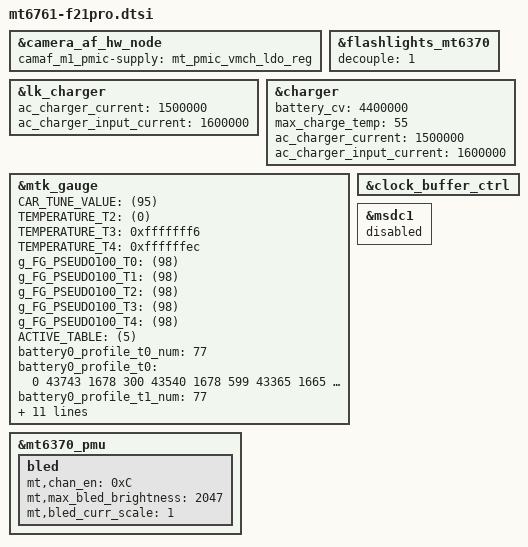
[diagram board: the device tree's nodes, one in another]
// SPDX-License-Identifier: GPL-2.0+
/*
 * Mon Mar 25 18:47:30 CST 2024 stock v4.19.127 boot.img overrides to make identical mt6761.dtb
 *
 * Copyright (c) 2019 MediaTek Inc.
 * Copyright (c) 2025 Jami Kettunen <jami.kettunen@protonmail.com>
 */


// mt6761.dts
&camera_af_hw_node {
	camaf_m1_pmic-supply = <&mt_pmic_vmch_ldo_reg>;
};

&flashlights_mt6370 {
	decouple = <1>;
	/delete-node/ channel@2;
};

&lk_charger {
	/* charging current */
	ac_charger_current = <1500000>;
	ac_charger_input_current = <1600000>;
};
&charger {
	/* common */
	battery_cv = <4400000>;

	/* battery temperature protection */
	max_charge_temp = <55>;

	/* charging current */
	ac_charger_current = <1500000>;
	ac_charger_input_current = <1600000>;
};


// bat_setting/mt6761_battery_prop.dtsi
&mtk_gauge {
	CAR_TUNE_VALUE = <(95)>;
	/* Tune value for current measurement */

	TEMPERATURE_T2 = <(0)>;
	/* Battery temperature T2 */
	TEMPERATURE_T3 = <0xfffffff6>;
	/* Battery temperature T3 */
	TEMPERATURE_T4 = <0xffffffec>;
	/* Battery temperature T4 */
	/delete-property/ TEMPERATURE_T5;
	/* Battery temperature T5 */
	g_FG_PSEUDO100_T0 = <(98)>;
	/* Pseudo 100% percentage at T0 */
	g_FG_PSEUDO100_T1 = <(98)>;
	/* Pseudo 100% percentage at T1 */
	g_FG_PSEUDO100_T2 = <(98)>;
	/* Pseudo 100% percentage at T2 */
	g_FG_PSEUDO100_T3 = <(98)>;
	/* Pseudo 100% percentage at T3 */
	g_FG_PSEUDO100_T4 = <(98)>;
	/* Pseudo 100% percentage at T4 */

	ACTIVE_TABLE = <(5)>;
	/* Table numbers per battery */


	// bat_setting/mt6761_battery_table_ext.dtsi
	battery0_profile_t0_num = <77>;
	battery0_profile_t0 =
	<
	0	43743	1678
	300	43540	1678
	599	43365	1665
	898	43201	1663
	1198	43040	1660
	1348	42960	1660
	1498	42880	1660
	1797	42723	1663
	2097	42566	1670
	2397	42408	1670
	2697	42253	1675
	2997	42098	1678
	3297	41945	1685
	3597	41791	1680
	3897	41642	1690
	4197	41493	1693
	4497	41347	1703
	4797	41202	1713
	5097	41059	1720
	5397	40918	1728
	5697	40781	1735
	5997	40646	1748
	6297	40513	1758
	6597	40383	1763
	6897	40256	1773
	7197	40134	1788
	7497	40015	1800
	7797	39898	1818
	8097	39786	1830
	8397	39676	1850
	8697	39567	1870
	8997	39458	1890
	9297	39342	1895
	9597	39213	1885
	9897	39059	1813
	10197	38905	1733
	10497	38779	1685
	10797	38678	1665
	11097	38592	1660
	11397	38514	1660
	11697	38441	1663
	11997	38373	1665
	12297	38310	1675
	12597	38249	1678
	12897	38191	1678
	13197	38136	1680
	13497	38086	1688
	13797	38038	1705
	14097	37992	1720
	14397	37949	1735
	14697	37909	1750
	14997	37868	1760
	15297	37829	1770
	15597	37789	1773
	15897	37742	1763
	16197	37679	1733
	16497	37594	1683
	16797	37524	1670
	17097	37468	1665
	17397	37410	1660
	17697	37351	1653
	17997	37301	1655
	18297	37255	1665
	18597	37203	1680
	18897	37128	1678
	19197	37042	1665
	19496	36968	1683
	19796	36868	1675
	20096	36787	1638
	20396	36770	1670
	20696	36756	1710
	20996	36734	1753
	21296	36680	1810
	21596	36420	1753
	21895	35807	1743
	22195	34910	1798
	22345	34160	1875
	>;

	battery0_profile_t1_num = <77>;
	battery0_profile_t1 =
	<
	0	43867	2235
	300	43608	2235
	600	43422	2258
	900	43253	2258
	1200	43092	2263
	1500	42932	2263
	1800	42772	2265
	2100	42615	2270
	2400	42459	2272
	2700	42304	2275
	3000	42148	2275
	3300	41995	2278
	3600	41843	2285
	3900	41691	2275
	4200	41541	2288
	4500	41394	2302
	4800	41248	2310
	5100	41103	2315
	5400	40961	2325
	5700	40821	2332
	6000	40686	2353
	6300	40554	2368
	6600	40424	2383
	6900	40279	2368
	7200	40132	2375
	7500	40008	2413
	7800	39897	2438
	8100	39782	2430
	8400	39665	2430
	8700	39543	2418
	9000	39415	2395
	9300	39279	2343
	9600	39139	2278
	9900	39004	2213
	10200	38879	2158
	10500	38770	2120
	10800	38672	2100
	11100	38584	2088
	11400	38504	2078
	11700	38430	2080
	12000	38361	2078
	12300	38296	2080
	12600	38233	2080
	12900	38176	2085
	13200	38119	2085
	13500	38067	2090
	13800	38016	2093
	14100	37967	2088
	14400	37921	2088
	14700	37878	2090
	15000	37835	2078
	15300	37795	2070
	15600	37757	2055
	15900	37724	2050
	16200	37692	2050
	16500	37660	2053
	16800	37626	2057
	17100	37586	2065
	17400	37538	2068
	17700	37487	2080
	18000	37434	2105
	18300	37381	2150
	18600	37320	2205
	18900	37243	2248
	19200	37157	2288
	19500	37072	2335
	19800	36974	2378
	20100	36876	2395
	20400	36827	2457
	20700	36798	2550
	21000	36762	2675
	21150	36730	2761
	21300	36697	2847
	21600	36509	3033
	21900	36020	3168
	22200	35193	3470
	22500	33857	4203
	>;

	battery0_profile_t2_num = <77>;
	battery0_profile_t2 = <
	0	43854	6398
	300	43346	6398
	600	42918	6325
	900	42552	6147
	1200	42229	6057
	1500	41940	5960
	1800	41683	5850
	2100	41450	5790
	2400	41231	5758
	2700	41036	5755
	2999	40864	5773
	3299	40685	5748
	3599	40491	5653
	3899	40311	5548
	4199	40162	5528
	4499	40024	5448
	4799	39893	5410
	5099	39768	5400
	5399	39644	5410
	5699	39521	5400
	5999	39402	5375
	6299	39288	5348
	6599	39173	5318
	6899	39063	5305
	7199	38957	5280
	7499	38853	5278
	7799	38754	5260
	8099	38659	5233
	8400	38567	5230
	8700	38481	5218
	9000	38400	5228
	9300	38323	5230
	9600	38253	5245
	9900	38189	5265
	10200	38133	5278
	10500	38089	5310
	10800	38054	5380
	11100	38024	5440
	11400	38001	5528
	11700	37979	5653
	12000	37959	5830
	12300	37936	6015
	12600	37912	6288
	12900	37885	6550
	13200	37855	6910
	13500	37823	7328
	13800	37790	7835
	14100	37756	8310
	14400	37724	8775
	14700	37692	9170
	14999	37661	9498
	15299	37629	9785
	15599	37599	10033
	15899	37566	10250
	16199	37531	10460
	16499	37496	10658
	16799	37458	10840
	17099	37418	11023
	17399	37375	11193
	17699	37328	11350
	17999	37277	11523
	18299	37223	11685
	18599	37164	11838
	18899	37099	11983
	19199	37030	12140
	19499	36957	12313
	19799	36888	12485
	20099	36825	12678
	20399	36770	12920
	20699	36718	13218
	20999	36657	13590
	21299	36558	14068
	21599	36357	14655
	21844	36053	15135
	22056	35684	14223
	22278	35073	12705
	22432	34462	11190
	>;

	battery0_profile_t3_num = <77>;
	battery0_profile_t3 =
	<
	0	43905	12533
	300	43322	12533
	600	42803	12430
	900	42337	12003
	1200	41927	11588
	1500	41564	11195
	1800	41241	10873
	2099	40974	10600
	2399	40690	10285
	2699	40402	9932
	2999	40178	9673
	3299	40011	9518
	3599	39859	9368
	3899	39716	9243
	4199	39582	9128
	4499	39453	9023
	4799	39334	8920
	5098	39220	8828
	5398	39114	8778
	5698	39013	8690
	5998	38918	8653
	6298	38827	8613
	6598	38740	8578
	6898	38659	8560
	7198	38580	8553
	7498	38507	8553
	7798	38438	8573
	8098	38376	8573
	8398	38323	8608
	8698	38276	8660
	8998	38237	8732
	9298	38203	8815
	9598	38173	8933
	9898	38144	9070
	10198	38117	9230
	10498	38091	9398
	10798	38064	9618
	11098	38035	9860
	11398	38007	10138
	11698	37975	10445
	11998	37945	10788
	12298	37912	11148
	12598	37879	11500
	12898	37844	11838
	13197	37810	12135
	13497	37776	12400
	13797	37742	12623
	14097	37707	12820
	14397	37672	13000
	14697	37636	13153
	14997	37600	13318
	15297	37564	13458
	15597	37526	13585
	15897	37487	13720
	16197	37448	13853
	16497	37407	13973
	16796	37366	14085
	17096	37324	14210
	17396	37280	14338
	17696	37237	14470
	17996	37193	14590
	18296	37147	14720
	18596	37100	14868
	18896	37052	15055
	19196	37002	15238
	19495	36948	15465
	19795	36889	15743
	20095	36819	16063
	20395	36738	16455
	20626	36673	16683
	20902	36606	16520
	21096	36549	16375
	21523	36357	15913
	21567	36329	15843
	21885	35995	15075
	22102	35638	14178
	22431	34554	11550
	>;

	battery0_profile_t4_num = <77>;
	battery0_profile_t4 =
	<
	0	43913	20270
	300	43200	20270
	600	42591	19628
	900	42085	18765
	1200	41658	17965
	1500	41296	17323
	1800	40976	16765
	2100	40636	16163
	2400	40323	15638
	2700	40084	15245
	3000	39892	14975
	3300	39721	14720
	3600	39562	14485
	3900	39412	14298
	4200	39273	14113
	4500	39143	13960
	4800	39023	13838
	5100	38913	13740
	5400	38811	13668
	5700	38717	13610
	6000	38632	13565
	6300	38558	13550
	6600	38491	13548
	6900	38434	13573
	7200	38384	13620
	7500	38340	13695
	7800	38300	13778
	8100	38263	13885
	8400	38252	12160
	8700	38242	10435
	9000	38169	13493
	9300	38125	14265
	9600	38089	14613
	9900	38052	14908
	10199	38016	15225
	10499	37978	15578
	10799	37940	15975
	11099	37901	16300
	11399	37861	16615
	11699	37822	16958
	11999	37782	17288
	12299	37744	17595
	12598	37707	17855
	12898	37668	18090
	13198	37631	18320
	13498	37593	18503
	13798	37556	18668
	14085	37520	18800
	14307	37500	18753
	14496	37485	18713
	14663	37472	18680
	14812	37461	18653
	14950	37450	18630
	15076	37441	18603
	15410	37417	18543
	15509	37409	18523
	15780	37390	18485
	15861	37384	18470
	16086	37368	18425
	16285	37355	18398
	16466	37342	18360
	16685	37325	18335
	16928	37308	18280
	17142	37293	18235
	17336	37276	18198
	17547	37257	18165
	17707	37244	18113
	17908	37225	18063
	18068	37208	18058
	18306	37182	17975
	18479	37161	17975
	18654	37139	17868
	18854	37111	17800
	19036	37083	17773
	19258	37045	17670
	19444	37010	17640
	19591	36984	17460
	>;

	/delete-property/ battery0_profile_t5_num;
	/delete-property/ battery0_profile_t5_col;
	/delete-property/ battery0_profile_t5;
};


// mt6357.dtsi
&clock_buffer_ctrl {
	/delete-property/ pmic-default-capid;
};


// cust_mt6761_msdc.dtsi
&msdc1 {
	status = "disabled";
};


// mt6370.dtsi
&mt6370_pmu {
	bled {
		mt,chan_en  = <0xC>; /* bit 0 1 2 3 -> chan 1 2 3 4 */

		/* we have 11 bit resolution, quantize in driver */
		mt,max_bled_brightness = <2047>; /* maximum 2047 */

		mt,bled_curr_scale = <1>;	/* 0: 30mA, 1: 22.5mA */
						/* 2: 20mA, 3: 17.5mA */
	};
};
